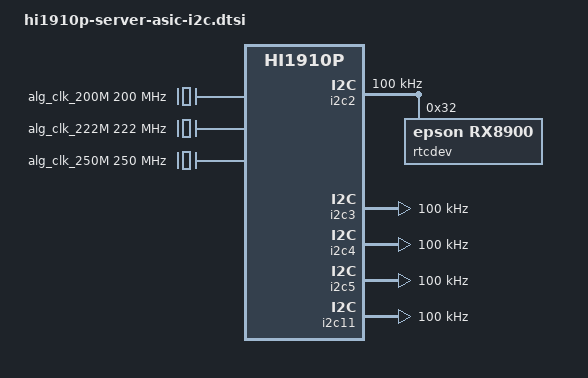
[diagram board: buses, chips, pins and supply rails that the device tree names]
i2c_pinctrl_4:i2c4_pinctrl@0xFA6E_0000{
	compatible = "i2c-mux-pinctrl";
	pinctrl-names = "default", "idle";
	pinctrl-0 = <&media000_pmx_func &media001_pmx_func &scl4_cfg_func &sda4_cfg_func>;
	pinctrl-1 = <&media000_pmx_idle &media001_pmx_idle &scl4_cfg_func &sda4_cfg_func>;
};

i2c_pinctrl_5:i2c5_pinctrl@0xFA6E_0008{
	compatible = "i2c-mux-pinctrl";
	pinctrl-names = "default", "idle";
	pinctrl-0 = <&media002_pmx_func &media003_pmx_func &scl5_cfg_func &sda5_cfg_func>;
	pinctrl-1 = <&media002_pmx_idle &media003_pmx_idle &scl5_cfg_func &sda5_cfg_func>;
};


i2c_pinctrl_11:i2c11_pinctrl@0x8402_00c0{
	compatible = "i2c-mux-pinctrl";
	pinctrl-names = "default", "idle";
	pinctrl-0 = <&aomg048_pmx_func &aomg049_pmx_func &scl11_cfg_func &sda11_cfg_func>;
	pinctrl-1 = <&aomg048_pmx_idle &aomg049_pmx_idle &scl11_cfg_func &sda11_cfg_func>;
};

alg_clk_200M: alg_clk_200M {
    compatible = "fixed-clock";
    #clock-cells = <0>;
    clock-frequency = <200000000>;
};

alg_clk_222M: alg_clk_222M {
    compatible = "fixed-clock";
    #clock-cells = <0>;
    clock-frequency = <222000000>;
};

alg_clk_250M: alg_clk_250M {
    compatible = "fixed-clock";
    #clock-cells = <0>;
    clock-frequency = <250000000>;
};

i2c2:i2c@00_8405_0000{
	#address-cells = <1>;
	#size-cells = <0>;
	compatible = "snps,designware-i2c";
	reg = <0x0 0x84050000 0 0x10000>;
	interrupts = <0x0 187 0x4>;
	i2c-sda-falling-time-ns = <913>;
	i2c-scl-falling-time-ns = <303>;
	i2c-sda-hold-time-ns = <0x190>;
	clocks = <&alg_clk_200M>;
	clock-frequency = <100000>;
	status = "ok";
	pinctrl-names = "default", "idle";
	pinctrl-0 = <&aomg040_pmx_func &aomg041_pmx_func &scl2_cfg_func &sda2_cfg_func>;
	pinctrl-1 = <&aomg040_pmx_idle &aomg041_pmx_idle &scl2_cfg_func &sda2_cfg_func>;
	rtcdev: rtc@0x32 {
	    compatible = "epson,rx8900";
	    reg = <0x32>;
	};
        //cplddev: cpld@0x33 {
        //    compatible = "cpld";
        //    reg = <0x33>;
        //};
};

i2c3:i2c@00_8406_0000{
	#address-cells = <1>;
	#size-cells = <0>;
	compatible = "snps,designware-i2c";
	reg = <0x0 0x84060000 0 0x10000>;
	interrupts = <0x0 188 0x4>;
	i2c-sda-falling-time-ns = <913>;
	i2c-scl-falling-time-ns = <303>;
	i2c-sda-hold-time-ns = <0x190>;
	clocks = <&alg_clk_200M>;
	clock-frequency = <100000>;
	status = "ok";
	pinctrl-names = "default", "idle";
	pinctrl-0 = <&aomg042_pmx_func &aomg043_pmx_func &scl3_cfg_func &sda3_cfg_func>;
	pinctrl-1 = <&aomg042_pmx_idle &aomg043_pmx_idle &scl3_cfg_func &sda3_cfg_func>;
};

i2c4:i2c@00_A218_0000{
	#address-cells = <1>;
	#size-cells = <0>;
	compatible = "snps,designware-i2c";
	reg = <0x0 0xA2180000 0 0x10000>;
	interrupts = <0x0 256 0x4>;
	i2c-sda-falling-time-ns = <946>;
	i2c-scl-falling-time-ns = <290>;
	i2c-sda-hold-time-ns = <0x190>;
	clocks = <&alg_clk_250M>;
	clock-frequency = <100000>;
};

i2c5:i2c@00_A219_0000{
	#address-cells = <1>;
	#size-cells = <0>;
	compatible = "snps,designware-i2c";
	reg = <0x0 0xA2190000 0 0x10000>;
	interrupts = <0x0 257 0x4>;
	i2c-sda-falling-time-ns = <946>;
	i2c-scl-falling-time-ns = <290>;
	i2c-sda-hold-time-ns = <0x190>;
	clocks = <&alg_clk_250M>;
	clock-frequency = <100000>;
};

i2c11:i2c@00_8407_0000{

	#address-cells = <1>;
	#size-cells = <0>;
	compatible = "snps,designware-i2c";
	reg = <0x0 0x84070000 0 0x10000>;
	interrupts = <0x0 329 0x4>;
	i2c-sda-falling-time-ns = <913>;
	i2c-scl-falling-time-ns = <303>;
	i2c-sda-hold-time-ns = <0x190>;
	clocks = <&alg_clk_200M>;
	clock-frequency = <100000>;

};
